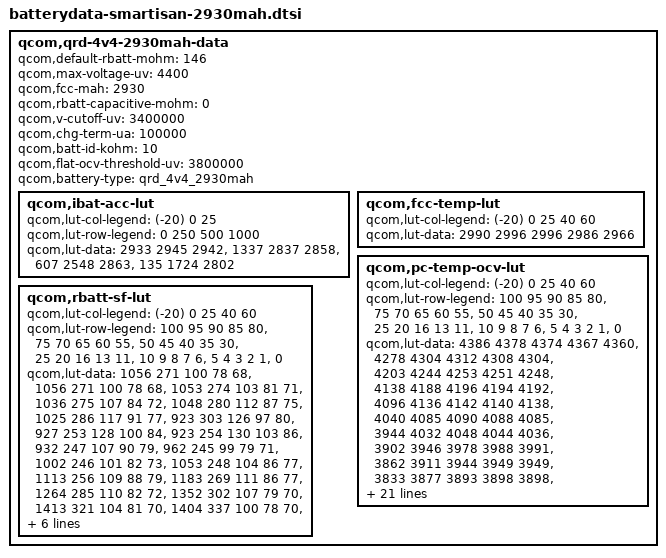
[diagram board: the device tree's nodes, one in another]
/* Copyright (c) 2013, The Linux Foundation. All rights reserved.
 *
 * This program is free software; you can redistribute it and/or modify
 * it under the terms of the GNU General Public License version 2 and
 * only version 2 as published by the Free Software Foundation.
 *
 * This program is distributed in the hope that it will be useful,
 * but WITHOUT ANY WARRANTY; without even the implied warranty of
 * MERCHANTABILITY or FITNESS FOR A PARTICULAR PURPOSE.  See the
 * GNU General Public License for more details.
 */

qcom,qrd-4v4-2930mah-data {
	qcom,default-rbatt-mohm = <146>;
	qcom,max-voltage-uv = <4400>;
	qcom,fcc-mah = <2930>;
	qcom,rbatt-capacitive-mohm = <0>;
	qcom,v-cutoff-uv = <3400000>;
	qcom,chg-term-ua = <100000>;
	qcom,batt-id-kohm = <10>;
	qcom,flat-ocv-threshold-uv = <3800000>;
	qcom,battery-type = "qrd_4v4_2930mah";

	qcom,ibat-acc-lut {
		qcom,lut-col-legend = <(-20) 0 25>;
		qcom,lut-row-legend = <0 250 500 1000>;
		qcom,lut-data = <2933 2945 2942>,
				<1337 2837 2858>,
				<607 2548 2863>,
				<135 1724 2802>;
	};
	
	qcom,fcc-temp-lut {
		qcom,lut-col-legend = <(-20) 0 25 40 60>;
		qcom,lut-data = <2990 2996 2996 2986 2966>;
	};

	qcom,pc-temp-ocv-lut {
		qcom,lut-col-legend = <(-20) 0 25 40 60>;
		qcom,lut-row-legend = <100 95 90 85 80>,
				<75 70 65 60 55>,
				<50 45 40 35 30>,
				<25 20 16 13 11>,
				<10 9 8 7 6>,
				<5 4 3 2 1>,
				<0>;
		qcom,lut-data = <4386 4378 4374 4367 4360>,
				<4278 4304 4312 4308 4304>,
				<4203 4244 4253 4251 4248>,
				<4138 4188 4196 4194 4192>,
				<4096 4136 4142 4140 4138>,
				<4040 4085 4090 4088 4085>,
				<3944 4032 4048 4044 4036>,
				<3902 3946 3978 3988 3991>,
				<3862 3911 3944 3949 3949>,
				<3833 3877 3893 3898 3898>,
				<3813 3846 3856 3858 3858>,
				<3798 3820 3830 3832 3832>,
				<3782 3798 3808 3810 3810>,
				<3768 3781 3790 3790 3790>,
				<3753 3768 3776 3772 3769>,
				<3738 3754 3760 3753 3742>,
				<3718 3735 3740 3730 3717>,
				<3700 3716 3710 3702 3688>,
				<3684 3704 3692 3682 3671>,
				<3670 3697 3688 3680 3670>,
				<3662 3694 3688 3680 3668>,
				<3650 3690 3686 3678 3667>,
				<3638 3684 3684 3676 3665>,
				<3624 3674 3680 3672 3658>,
				<3604 3656 3665 3652 3635>,
				<3576 3624 3629 3614 3596>,
				<3540 3578 3578 3563 3545>,
				<3488 3518 3512 3498 3480>,
				<3409 3435 3424 3411 3394>,
				<3280 3294 3300 3279 3264>,
				<3010 3000 3019 3000 3000>;
	};

	qcom,rbatt-sf-lut {
		qcom,lut-col-legend = <(-20) 0 25 40 60>;
		qcom,lut-row-legend = <100 95 90 85 80>,
				<75 70 65 60 55>,
				<50 45 40 35 30>,
				<25 20 16 13 11>,
				<10 9 8 7 6>,
				<5 4 3 2 1>,
				<0>;
		qcom,lut-data = <1056 271 100 78 68>,
				<1056 271 100 78 68>,
				<1053 274 103 81 71>,
				<1036 275 107 84 72>,
				<1048 280 112 87 75>,
				<1025 286 117 91 77>,
				<923 303 126 97 80>,
				<927 253 128 100 84>,
				<923 254 130 103 86>,
				<932 247 107 90 79>,
				<962 245 99 79 71>,
				<1002 246 101 82 73>,
				<1053 248 104 86 77>,
				<1113 256 109 88 79>,
				<1183 269 111 86 77>,
				<1264 285 110 82 72>,
				<1352 302 107 79 70>,
				<1413 321 104 81 70>,
				<1404 337 100 78 70>,
				<1364 338 103 82 73>,
				<1393 348 107 84 74>,
				<1425 360 111 87 75>,
				<1465 374 115 89 77>,
				<1518 388 118 89 75>,
				<1620 396 116 86 73>,
				<1756 404 111 84 74>,
				<1996 422 114 86 77>,
				<2342 448 119 92 82>,
				<2921 485 133 107 91>,
				<4329 682 182 141 111>,
				<8659 1363 363 282 222>;
	};
};
